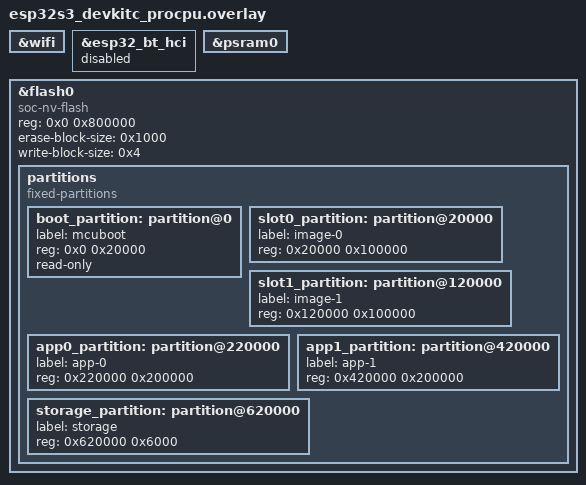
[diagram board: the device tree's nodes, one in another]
/*
 * Copyright (c) 2022 Espressif Systems (Shanghai) Co., Ltd.
 *
 * SPDX-License-Identifier: Apache-2.0
 */

&wifi {
  status = "okay";
};

&esp32_bt_hci {
  status = "disabled";
};

&psram0 {
  status = "okay";
};

/delete-node/ &boot_partition;
/delete-node/ &slot0_partition;
/delete-node/ &slot1_partition;
/delete-node/ &scratch_partition;
/delete-node/ &storage_partition;

&flash0 {
  compatible = "soc-nv-flash";
  reg = < 0x0 0x800000 >;
  erase-block-size = < 0x1000 >;
  write-block-size = < 0x4 >;
  status = "okay";
  partitions {
    compatible = "fixed-partitions";
    #address-cells = < 0x1 >;
    #size-cells = < 0x1 >;
    boot_partition: partition@0 {
      label = "mcuboot";
      reg = < 0x0 0x20000 >;
      read-only;
    };
    slot0_partition: partition@20000 {
      label = "image-0";
      reg = < 0x20000 0x100000 >;
    };
    slot1_partition: partition@120000 {
      label = "image-1";
      reg = < 0x120000 0x100000 >;
    };
    app0_partition: partition@220000 {
      label = "app-0";
      reg = < 0x220000 0x200000 >;
    };
    app1_partition: partition@420000 {
      label = "app-1";
      reg = < 0x420000 0x200000 >;
    };
    storage_partition: partition@620000 {
      label = "storage";
      reg = < 0x620000 0x6000 >;
    };
  };
};
